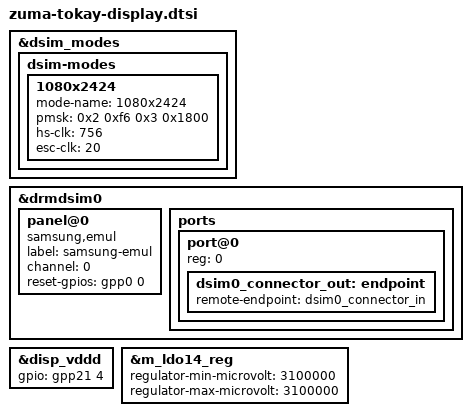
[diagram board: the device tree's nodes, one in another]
// SPDX-License-Identifier: GPL-2.0-only
/*
 * Display nodes for tokay-related boards.
 *
 * Copyright 2023 Google LLC
 *
 */

#include <dt-bindings/gpio/gpio.h>
#include "zuma-tokay-connector.dtsi"

&dsim_modes {
	dsim-modes {
		1080x2424 {
			mode-name = "1080x2424";
			pmsk = <
				0x2 0xf6 0x3 0x1800 /* p m s k */
				>;
			hs-clk = <756>;
			esc-clk = <20>;
		};
	};
};

&drmdsim0 {
	#address-cells = <1>;
	#size-cells = <0>;

	panel@0 {
		compatible = "samsung,emul";
		label = "samsung-emul";
		channel = <0>;

		/* reset, power */
		reset-gpios = <&gpp0 0 GPIO_ACTIVE_HIGH>;
	};

	ports {
		#address-cells = <1>;
		#size-cells = <0>;
		port@0 {
			reg = <0>;
			/* output */
			dsim0_connector_out: endpoint {
				remote-endpoint = <&dsim0_connector_in>;
			};
		};
	};
};

&disp_vddd {
	status = "okay";
	gpio = <&gpp21 4 GPIO_ACTIVE_HIGH>;
};

&m_ldo14_reg {
	regulator-min-microvolt = <3100000>;
	regulator-max-microvolt = <3100000>;
};
